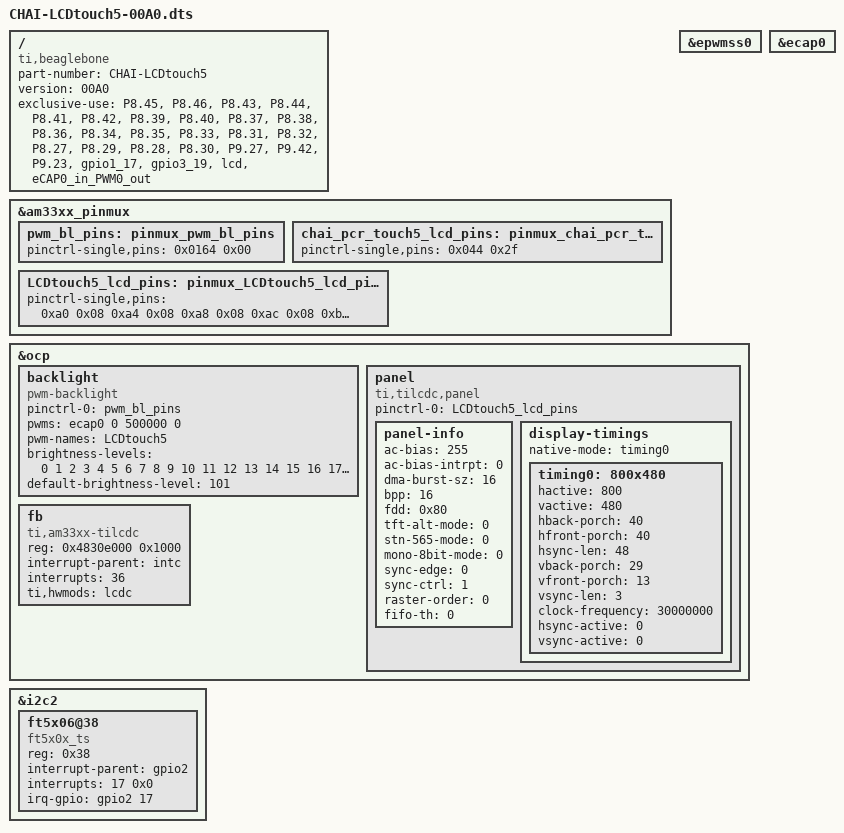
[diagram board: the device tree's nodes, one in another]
/* 
 * CHAI PCR PROJECT 5" Capacitive touchscreen LCD for
 */
/dts-v1/;
/plugin/;

/ {
	compatible = "ti,beaglebone", "ti,beaglebone-black";

	/* identification */
	part-number = "CHAI-LCDtouch5";
	version = "00A0";

	/* state the resources this cape uses */
	exclusive-use =
		/* the pin header uses */
		"P8.45",	/* lcd: lcd_data0 */
		"P8.46",	/* lcd: lcd_data1 */
		"P8.43",	/* lcd: lcd_data2 */
		"P8.44",	/* lcd: lcd_data3 */
		"P8.41",	/* lcd: lcd_data4 */
		"P8.42",	/* lcd: lcd_data5 */
		"P8.39",	/* lcd: lcd_data6 */
		"P8.40",	/* lcd: lcd_data7 */
		"P8.37",	/* lcd: lcd_data8 */
		"P8.38",	/* lcd: lcd_data9 */
		"P8.36",	/* lcd: lcd_data10 */
		"P8.34",	/* lcd: lcd_data11 */
		"P8.35",	/* lcd: lcd_data12 */
		"P8.33",	/* lcd: lcd_data13 */
		"P8.31",	/* lcd: lcd_data14 */
		"P8.32",	/* lcd: lcd_data15 */
		"P8.27",	/* lcd: lcd_vsync */
		"P8.29",	/* lcd: lcd_hsync */
		"P8.28",	/* lcd: lcd_pclk */
		"P8.30",	/* lcd: lcd_ac_bias_en */
		"P9.27",	/* lcd: gpio3_19 */
		"P9.42",	/* pwm: eCAP0 */
                "P9.23",	/* touch: gpio1_17 */
		/* the hardware IP uses */
                "gpio1_17",
		"gpio3_19",
		"lcd",
		"eCAP0_in_PWM0_out";

	fragment@0 {
		target = <&am33xx_pinmux>;
		__overlay__ {

			pwm_bl_pins: pinmux_pwm_bl_pins {
				pinctrl-single,pins = <
					0x0164 0x00  /* P9.42.1 eCAP0_PWM0, MODE0 */
				>;
			};

                        chai_pcr_touch5_lcd_pins: 
pinmux_chai_pcr_touch5_lcd_pins {
				pinctrl-single,pins = <
					0x044 0x2f	/* TSC_INTn gpmc_a1.gpio1_17, INPUT | PULLDIS | MODE7 */
				>;
			};
            
			LCDtouch5_lcd_pins: 
pinmux_LCDtouch5_lcd_pins {
				pinctrl-single,pins = <
					0xa0 0x08	/* lcd_data0.lcd_data0, OMAP_MUX_MODE0 | AM33XX_PIN_OUTPUT | AM33XX_PULL_DISA */
					0xa4 0x08	/* lcd_data1.lcd_data1, OMAP_MUX_MODE0 | AM33XX_PIN_OUTPUT | AM33XX_PULL_DISA */
					0xa8 0x08	/* lcd_data2.lcd_data2, OMAP_MUX_MODE0 | AM33XX_PIN_OUTPUT | AM33XX_PULL_DISA */
					0xac 0x08	/* lcd_data3.lcd_data3, OMAP_MUX_MODE0 | AM33XX_PIN_OUTPUT | AM33XX_PULL_DISA */
					0xb0 0x08	/* lcd_data4.lcd_data4, OMAP_MUX_MODE0 | AM33XX_PIN_OUTPUT | AM33XX_PULL_DISA */
					0xb4 0x08	/* lcd_data5.lcd_data5, OMAP_MUX_MODE0 | AM33XX_PIN_OUTPUT | AM33XX_PULL_DISA */
					0xb8 0x08	/* lcd_data6.lcd_data6, OMAP_MUX_MODE0 | AM33XX_PIN_OUTPUT | AM33XX_PULL_DISA */
					0xbc 0x08	/* lcd_data7.lcd_data7, OMAP_MUX_MODE0 | AM33XX_PIN_OUTPUT | AM33XX_PULL_DISA */
					0xc0 0x08	/* lcd_data8.lcd_data8, OMAP_MUX_MODE0 | AM33XX_PIN_OUTPUT | AM33XX_PULL_DISA */
					0xc4 0x08	/* lcd_data9.lcd_data9, OMAP_MUX_MODE0 | AM33XX_PIN_OUTPUT | AM33XX_PULL_DISA */
					0xc8 0x08	/* lcd_data10.lcd_data10, OMAP_MUX_MODE0 | AM33XX_PIN_OUTPUT | AM33XX_PULL_DISA */
					0xcc 0x08	/* lcd_data11.lcd_data11, OMAP_MUX_MODE0 | AM33XX_PIN_OUTPUT | AM33XX_PULL_DISA */
					0xd0 0x08	/* lcd_data12.lcd_data12, OMAP_MUX_MODE0 | AM33XX_PIN_OUTPUT | AM33XX_PULL_DISA */
					0xd4 0x08	/* lcd_data13.lcd_data13, OMAP_MUX_MODE0 | AM33XX_PIN_OUTPUT | AM33XX_PULL_DISA */
					0xd8 0x08	/* lcd_data14.lcd_data14, OMAP_MUX_MODE0 | AM33XX_PIN_OUTPUT | AM33XX_PULL_DISA */
					0xdc 0x08	/* lcd_data15.lcd_data15, OMAP_MUX_MODE0 | AM33XX_PIN_OUTPUT | AM33XX_PULL_DISA */
					0xe0 0x00	/* lcd_vsync.lcd_vsync, OMAP_MUX_MODE0 | AM33XX_PIN_OUTPUT */
					0xe4 0x00	/* lcd_hsync.lcd_hsync, OMAP_MUX_MODE0 | AM33XX_PIN_OUTPUT */
					0xe8 0x00	/* lcd_pclk.lcd_pclk, OMAP_MUX_MODE0 | AM33XX_PIN_OUTPUT */
					0xec 0x00	/* lcd_ac_bias_en.lcd_ac_bias_en, OMAP_MUX_MODE0 | AM33XX_PIN_OUTPUT */
					0x1a4 0x17	/* mcasp0_fsr.gpio3_19, OUTPUT | MODE7  LCD DISEN */
				>;
			};

			

		};
	};

	fragment@1 {
		target = <&epwmss0>;
		__overlay__ {
			status = "okay";
		};
	};

	fragment@2 {
		target = <&ecap0>;
	    	__overlay__ {
		    status = "okay";
	   	};
	};

	fragment@3 {
		target = <&ocp>;

		__overlay__ {

			/* avoid stupid warning */
			#address-cells = <1>;
			#size-cells = <1>;

			backlight {
				compatible      = "pwm-backlight";
 				pinctrl-names   = "default";
				pinctrl-0       = <&pwm_bl_pins>;

				pwms = <&ecap0 0 500000 0>;
				pwm-names = "LCDtouch5";
				brightness-levels = <0 1 2 3 4 5 6 7 8 9 10 11 12 13 14 15 16 17 18 19 20 21 22 23 24 25 26 27 28 29 30 31 32 33 34 35 36 37 38 39 40 41 42 43 44 45 46 47 48 49 50 51 52 53 54 55 56 57 58 59 60 61 62 63 64 65 66 67 68 69 70 71 72 73 74 75 76 77 78 79 80 81 82 83 84 85 86 87 88 89 90 91 92 93 94 95 96 97 98 99 100>;
				default-brightness-level = <101>; /* index to the array above */
				status = "okay";
 			};

			


			/* Settings for TF-SPEC50002C-V0 / chai-pcr lcd: */
			panel {
				compatible = "ti,tilcdc,panel";
				pinctrl-names = "default";
				pinctrl-0 = <&LCDtouch5_lcd_pins>;
				panel-info {
					ac-bias           = <255>;
					ac-bias-intrpt    = <0>;
					dma-burst-sz      = <16>;
					bpp               = <16>;
					fdd               = <0x80>;
					tft-alt-mode      = <0>;
					stn-565-mode      = <0>;
					mono-8bit-mode    = <0>;
					sync-edge         = <0>;
					sync-ctrl         = <1>;
					raster-order      = <0>;
					fifo-th           = <0>;
				};
				display-timings {
					native-mode = <&timing0>;
					timing0: 800x480 {
						hactive         = <800>;
						vactive         = <480>;
						hback-porch     = <40>;
						hfront-porch    = <40>;
						hsync-len       = <48>;
						vback-porch     = <29>;
						vfront-porch    = <13>;
						vsync-len       = <3>;
						clock-frequency = <30000000>;
						hsync-active    = <0>;
						vsync-active    = <0>;
					};
				};
			};

			fb {
				compatible = "ti,am33xx-tilcdc";
				reg = <0x4830e000 0x1000>;
				interrupt-parent = <&intc>;
				interrupts = <36>;
				ti,hwmods = "lcdc";
			};

		};
	};
    
        fragment@4 {
               target = <&i2c2>;
               __overlay__ {

		       /* needed to avoid gripping by DTC */
		       #address-cells = <1>;
		       #size-cells = <0>;

			ft5x06@38 {
				compatible = "ft5x0x_ts";
				reg = <0x38>;
				interrupt-parent = <&gpio2>;
				interrupts = <17 0x0>;
				irq-gpio = <&gpio2 17 0>;
			};

               };
       };
};
